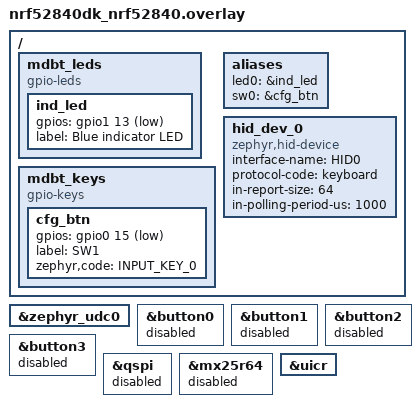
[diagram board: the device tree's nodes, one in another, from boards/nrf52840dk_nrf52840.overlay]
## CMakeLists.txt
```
# SPDX-License-Identifier: Apache-2.0

cmake_minimum_required(VERSION 3.20.0)
find_package(Zephyr REQUIRED HINTS $ENV{ZEPHYR_BASE})
project(ble_password)

include(${ZEPHYR_BASE}/samples/subsys/usb/common/common.cmake)
FILE(GLOB app_sources src/*.c)
target_sources(app PRIVATE ${app_sources})

# The app is an MCUboot image (sysbuild.conf); BLE update packages come from
# sysbuild as <build>/dfu_application.zip.  The official dongle's one-time
# Nordic-bootloader migration package (MCUboot only) is made in sysbuild.cmake.
```

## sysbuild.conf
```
# Both boards run the app under MCUboot so it can be updated over BLE (SMP)
# from the companion Android app.  Flash layouts: pm_static_<board>.yml.
# MCUboot's own config: sysbuild/mcuboot/.
SB_CONFIG_BOOTLOADER_MCUBOOT=y
```

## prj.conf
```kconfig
# BLE Observer (beacon scanning) + Peripheral (GATT config service)
CONFIG_BT=y
CONFIG_BT_OBSERVER=y
CONFIG_BT_PERIPHERAL=y
CONFIG_BT_DEVICE_NAME="BLE_Password"
CONFIG_BT_LOG_LEVEL_WRN=y

# Large ATT MTU / data length: a full password fits in one GATT write, and
# SMP firmware upload runs at a usable speed.
CONFIG_BT_L2CAP_TX_MTU=498
CONFIG_BT_BUF_ACL_TX_SIZE=502
CONFIG_BT_BUF_ACL_RX_SIZE=502
CONFIG_BT_CTLR_DATA_LENGTH_MAX=251

# Persist config in flash via the RAW flash API at the 'config_storage'
# partition (pm_static_*.yml).  Flash uses the default MPSL radio sync so SMP
# can erase/write the upload slot DURING a BLE connection; the config save
# still runs with bt_disable() as before.
CONFIG_FLASH=y
CONFIG_FLASH_MAP=y

# --- Firmware update: MCUboot + MCUmgr/SMP over BLE -----------------------
# MCUboot itself is enabled in sysbuild.conf.  SMP is locked by the app (see
# smp_gate_cb in main.c) unless DFU was armed with the button held.
CONFIG_ZCBOR=y
CONFIG_NET_BUF=y
CONFIG_CRC=y
CONFIG_MCUMGR=y
CONFIG_MCUMGR_TRANSPORT_BT=y
CONFIG_MCUMGR_TRANSPORT_BT_REASSEMBLY=y
CONFIG_MCUMGR_TRANSPORT_BT_CONN_PARAM_CONTROL=y
CONFIG_MCUMGR_TRANSPORT_NETBUF_SIZE=2475
CONFIG_MCUMGR_TRANSPORT_WORKQUEUE_STACK_SIZE=4608
CONFIG_MCUMGR_GRP_IMG=y
CONFIG_MCUMGR_GRP_OS=y
CONFIG_MCUMGR_GRP_OS_MCUMGR_PARAMS=y
CONFIG_MCUMGR_MGMT_NOTIFICATION_HOOKS=y
CONFIG_MCUMGR_SMP_COMMAND_STATUS_HOOKS=y
CONFIG_IMG_MANAGER=y
CONFIG_STREAM_FLASH=y
# SMP "reset" after an upload.
CONFIG_REBOOT=y

# --- Encrypted config session (fw 1.2.0+) ----------------------------------
# P-256 ECDH via PSA crypto on the CC310 (src/cfg_crypto.h); the KDF/sealing is
# our own HMAC code.  ECDH runs in the BT RX thread (GATT write), so its stack
# is enlarged.
CONFIG_NRF_SECURITY=y
CONFIG_MBEDTLS_PSA_CRYPTO_C=y
CONFIG_PSA_WANT_ALG_ECDH=y
CONFIG_PSA_WANT_ECC_SECP_R1_256=y
CONFIG_PSA_WANT_KEY_TYPE_ECC_KEY_PAIR_GENERATE=y
CONFIG_PSA_WANT_KEY_TYPE_ECC_KEY_PAIR_IMPORT=y
CONFIG_PSA_WANT_KEY_TYPE_ECC_KEY_PAIR_EXPORT=y
CONFIG_PSA_WANT_KEY_TYPE_ECC_KEY_PAIR_DERIVE=y
CONFIG_PSA_WANT_KEY_TYPE_ECC_PUBLIC_KEY=y
CONFIG_PSA_WANT_GENERATE_RANDOM=y
CONFIG_BT_RX_STACK_SIZE=4096

# Hardware watchdog (fail closed: a hang/crash resets the dongle and that boot
# locks the PC) + reset-cause readout.  MCUboot feeds it during swaps.
CONFIG_WATCHDOG=y
CONFIG_HWINFO=y

# USB HID — new stack (avoids dual-stack linker conflict seen on nRF52840 Dongle)
CONFIG_USB_DEVICE_STACK_NEXT=y
CONFIG_USB_DEVICE_STACK=n
CONFIG_USBD_HID_SUPPORT=y
CONFIG_USBD_LOG_LEVEL_WRN=y
CONFIG_USBD_HID_LOG_LEVEL_WRN=y
CONFIG_UDC_DRIVER_LOG_LEVEL_WRN=y
CONFIG_SAMPLE_USBD_PID=0x0008

# GPIO + button input subsystem
CONFIG_GPIO=y
CONFIG_INPUT=y
CONFIG_INPUT_MODE_SYNCHRONOUS=y

# Logging — disabled; CDC ACM serial removed so USB is HID-only
# (CDC ACM composite with HID is unstable on this dongle / next USB stack).
CONFIG_LOG=n
CONFIG_UART_CONSOLE=n
CONFIG_BOARD_SERIAL_BACKEND_CDC_ACM=n

# Larger stacks for BLE + USB combo
CONFIG_MAIN_STACK_SIZE=4096
CONFIG_SYSTEM_WORKQUEUE_STACK_SIZE=4096
```

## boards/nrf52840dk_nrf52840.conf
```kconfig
# Board-specific config for the 3rd-party Raytac MDBT50Q-RX dongle
# (built on the nrf52840dk target, flashed via J-Link).

# The module's 32.768 kHz crystal is optional / may not be populated, and the
# DK target defaults to the external crystal (LFXO).  Use the internal RC
# oscillator so BLE's low-frequency clock starts without a crystal — otherwise
# bt_enable() stalls and the app never reaches the config window.
CONFIG_CLOCK_CONTROL_NRF_K32SRC_RC=y

# Debug logging over SEGGER RTT (read with J-Link; this board has SWD).
CONFIG_LOG=y
CONFIG_LOG_MODE_DEFERRED=y
CONFIG_USE_SEGGER_RTT=y
CONFIG_LOG_BACKEND_RTT=y
CONFIG_LOG_BACKEND_UART=n
CONFIG_CONSOLE=n
CONFIG_UART_CONSOLE=n

# MCUboot + MCUmgr/SMP (firmware update over BLE) are common to both boards:
# see prj.conf, sysbuild.conf and sysbuild/mcuboot/.
```

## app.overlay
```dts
/*
 * LEDs and button use the nRF52840 Dongle board aliases directly:
 *   led0  = green single LED  (P0.06)
 *   led1  = RGB red           (P0.08)
 *   led3  = RGB blue          (P0.12)
 *   sw0   = SW1 button        (P1.06) — already wired to INPUT_KEY_0 by board DTS
 */

/ {
	hid_dev_0: hid_dev_0 {
		compatible = "zephyr,hid-device";
		interface-name = "HID0";
		protocol-code = "keyboard";
		in-report-size = <64>;
		in-polling-period-us = <1000>;
	};
};
```

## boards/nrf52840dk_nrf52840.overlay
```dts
/*
 * Overlay for the 3rd-party Raytac MDBT50Q-RX USB dongle, built on the
 * nrf52840dk board target (which boots from 0x0 → flashed standalone via J-Link).
 *
 * Board hardware:
 *   - single blue LED on P1.13 (active low)   (D2/P1.11 is not populated)
 *   - button on P0.15 (active low, pull-up)
 *   - USB on the nRF52840 USB peripheral
 */
#include <zephyr/dt-bindings/gpio/gpio.h>
#include <zephyr/dt-bindings/input/input-event-codes.h>

/ {
	mdbt_leds {
		compatible = "gpio-leds";
		ind_led: ind_led {
			gpios = <&gpio1 13 GPIO_ACTIVE_LOW>;
			label = "Blue indicator LED";
		};
	};

	mdbt_keys {
		compatible = "gpio-keys";
		cfg_btn: cfg_btn {
			gpios = <&gpio0 15 (GPIO_ACTIVE_LOW | GPIO_PULL_UP)>;
			label = "SW1";
			zephyr,code = <INPUT_KEY_0>;
		};
	};

	aliases {
		led0 = &ind_led;
		sw0 = &cfg_btn;
	};

	/* USB HID keyboard (same as the app.overlay used for the dongle build). */
	hid_dev_0: hid_dev_0 {
		compatible = "zephyr,hid-device";
		interface-name = "HID0";
		protocol-code = "keyboard";
		in-report-size = <64>;
		in-polling-period-us = <1000>;
	};
};

/* Make sure the USB device controller is available for HID. */
&zephyr_udc0 {
	status = "okay";
};

/* Disable the DK's on-board buttons so their pins (P0.11 etc.) don't emit
 * INPUT_KEY_0 and interfere with our button on P0.15. */
&button0 { status = "disabled"; };
&button1 { status = "disabled"; };
&button2 { status = "disabled"; };
&button3 { status = "disabled"; };

/* On the MDBT50Q-RX, module pins P0.18 (nRESET) and P0.19 are tied together.
 * The DK's QSPI flash (not fitted here) has SCK on P0.19: the QSPI driver
 * pulled the reset pin low and reset-looped the chip before main(), so SWD
 * couldn't even power up the DAP ("bricked" two units). Drop the QSPI flash,
 * and don't make P0.18 a reset pin (the DK writes UICR.PSELRESET at boot). */
&qspi { status = "disabled"; };
&mx25r64 { status = "disabled"; };
&uicr { /delete-property/ gpio-as-nreset; };
```

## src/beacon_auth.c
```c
/*
 * SPDX-License-Identifier: Apache-2.0
 *
 * SHA-256 / HMAC-SHA256 and the rolling-beacon check (see beacon_auth.h).
 * SHA-256 follows FIPS 180-4; verified against the FIPS and RFC 4231 vectors
 * in tests/host/beacon_auth_test.c.
 */
#include "beacon_auth.h"

#include <string.h>

struct sha256_ctx {
	uint32_t h[8];
	uint8_t  block[64];
	size_t   used;     /* bytes in block */
	uint64_t total;    /* message length in bytes */
};

static const uint32_t K[64] = {
	0x428a2f98, 0x71374491, 0xb5c0fbcf, 0xe9b5dba5, 0x3956c25b, 0x59f111f1,
	0x923f82a4, 0xab1c5ed5, 0xd807aa98, 0x12835b01, 0x243185be, 0x550c7dc3,
	0x72be5d74, 0x80deb1fe, 0x9bdc06a7, 0xc19bf174, 0xe49b69c1, 0xefbe4786,
	0x0fc19dc6, 0x240ca1cc, 0x2de92c6f, 0x4a7484aa, 0x5cb0a9dc, 0x76f988da,
	0x983e5152, 0xa831c66d, 0xb00327c8, 0xbf597fc7, 0xc6e00bf3, 0xd5a79147,
	0x06ca6351, 0x14292967, 0x27b70a85, 0x2e1b2138, 0x4d2c6dfc, 0x53380d13,
	0x650a7354, 0x766a0abb, 0x81c2c92e, 0x92722c85, 0xa2bfe8a1, 0xa81a664b,
	0xc24b8b70, 0xc76c51a3, 0xd192e819, 0xd6990624, 0xf40e3585, 0x106aa070,
	0x19a4c116, 0x1e376c08, 0x2748774c, 0x34b0bcb5, 0x391c0cb3, 0x4ed8aa4a,
	0x5b9cca4f, 0x682e6ff3, 0x748f82ee, 0x78a5636f, 0x84c87814, 0x8cc70208,
	0x90befffa, 0xa4506ceb, 0xbef9a3f7, 0xc67178f2,
};

static uint32_t rotr(uint32_t x, unsigned int n)
{
	return (x >> n) | (x << (32u - n));
}

static void sha256_compress(struct sha256_ctx *c, const uint8_t *p)
{
	uint32_t w[64];

	for (int i = 0; i < 16; i++) {
		w[i] = ((uint32_t)p[4 * i] << 24) | ((uint32_t)p[4 * i + 1] << 16) |
		       ((uint32_t)p[4 * i + 2] << 8) | (uint32_t)p[4 * i + 3];
	}
	for (int i = 16; i < 64; i++) {
		uint32_t s0 = rotr(w[i - 15], 7) ^ rotr(w[i - 15], 18) ^ (w[i - 15] >> 3);
		uint32_t s1 = rotr(w[i - 2], 17) ^ rotr(w[i - 2], 19) ^ (w[i - 2] >> 10);

		w[i] = w[i - 16] + s0 + w[i - 7] + s1;
	}

	uint32_t a = c->h[0], b = c->h[1], cc = c->h[2], d = c->h[3];
	uint32_t e = c->h[4], f = c->h[5], g = c->h[6], h = c->h[7];

	for (int i = 0; i < 64; i++) {
		uint32_t s1 = rotr(e, 6) ^ rotr(e, 11) ^ rotr(e, 25);
		uint32_t ch = (e & f) ^ (~e & g);
		uint32_t t1 = h + s1 + ch + K[i] + w[i];
		uint32_t s0 = rotr(a, 2) ^ rotr(a, 13) ^ rotr(a, 22);
		uint32_t maj = (a & b) ^ (a & cc) ^ (b & cc);
		uint32_t t2 = s0 + maj;

		h = g;
		g = f;
		f = e;
		e = d + t1;
		d = cc;
		cc = b;
		b = a;
		a = t1 + t2;
	}

	c->h[0] += a;
	c->h[1] += b;
	c->h[2] += cc;
	c->h[3] += d;
	c->h[4] += e;
	c->h[5] += f;
	c->h[6] += g;
	c->h[7] += h;
}

static void sha256_init(struct sha256_ctx *c)
{
	static const uint32_t iv[8] = {
		0x6a09e667, 0xbb67ae85, 0x3c6ef372, 0xa54ff53a,
		0x510e527f, 0x9b05688c, 0x1f83d9ab, 0x5be0cd19,
	};

	memcpy(c->h, iv, sizeof(iv));
	c->used = 0;
	c->total = 0;
}

static void sha256_update(struct sha256_ctx *c, const uint8_t *p, size_t len)
{
	c->total += len;
	while (len > 0) {
		size_t n = sizeof(c->block) - c->used;

		if (n > len) {
			n = len;
		}
		memcpy(c->block + c->used, p, n);
		c->used += n;
		p += n;
		len -= n;
		if (c->used == sizeof(c->block)) {
			sha256_compress(c, c->block);
			c->used = 0;
		}
	}
}

static void sha256_final(struct sha256_ctx *c, uint8_t out[SHA256_DIGEST_LEN])
{
	uint64_t bits = c->total * 8u;
	uint8_t pad = 0x80;

	sha256_update(c, &pad, 1);
	pad = 0;
	while (c->used != 56) {
		sha256_update(c, &pad, 1);
	}
	uint8_t len_be[8];

	for (int i = 0; i < 8; i++) {
		len_be[i] = (uint8_t)(bits >> (56 - 8 * i));
	}
	sha256_update(c, len_be, sizeof(len_be));

	for (int i = 0; i < 8; i++) {
		out[4 * i]     = (uint8_t)(c->h[i] >> 24);
		out[4 * i + 1] = (uint8_t)(c->h[i] >> 16);
		out[4 * i + 2] = (uint8_t)(c->h[i] >> 8);
		out[4 * i + 3] = (uint8_t)c->h[i];
	}
}

void sha256(const uint8_t *msg, size_t len, uint8_t out[SHA256_DIGEST_LEN])
{
	struct sha256_ctx c;

	sha256_init(&c);
	sha256_update(&c, msg, len);
	sha256_final(&c, out);
}

void hmac_sha256(const uint8_t *key, size_t key_len,
		 const uint8_t *msg, size_t msg_len,
		 uint8_t out[SHA256_DIGEST_LEN])
{
	uint8_t pad[64];
	uint8_t inner[SHA256_DIGEST_LEN];
	struct sha256_ctx c;

	if (key_len > sizeof(pad)) {
		key_len = sizeof(pad);   /* not used with long keys; see header */
	}

	memset(pad, 0x36, sizeof(pad));
	for (size_t i = 0; i < key_len; i++) {
		pad[i] ^= key[i];
	}
	sha256_init(&c);
	sha256_update(&c, pad, sizeof(pad));
	sha256_update(&c, msg, msg_len);
	sha256_final(&c, inner);

	memset(pad, 0x5c, sizeof(pad));
	for (size_t i = 0; i < key_len; i++) {
		pad[i] ^= key[i];
	}
	sha256_init(&c);
	sha256_update(&c, pad, sizeof(pad));
	sha256_update(&c, inner, sizeof(inner));
	sha256_final(&c, out);

	memset(pad, 0, sizeof(pad));
}

bool beacon_auth_is_beacon(const uint8_t *mfg, size_t len)
{
	return len == BEACON_MFG_LEN &&
	       mfg[0] == (uint8_t)(BEACON_COMPANY_ID & 0xFF) &&
	       mfg[1] == (uint8_t)(BEACON_COMPANY_ID >> 8) &&
	       mfg[2] == BEACON_MAGIC0 && mfg[3] == BEACON_MAGIC1 &&
	       mfg[4] == BEACON_VERSION;
}

bool beacon_auth_verify(const uint8_t key[BEACON_KEY_LEN],
			const uint8_t *mfg, size_t len, uint32_t *ctr)
{
	if (!beacon_auth_is_beacon(mfg, len)) {
		return false;
	}

	/* Signed part: magic, version, counter (7 bytes after the company ID). */
	uint8_t mac[SHA256_DIGEST_LEN];

	hmac_sha256(key, BEACON_KEY_LEN, &mfg[2], 7, mac);

	/* Constant-time compare. */
	uint8_t diff = 0;

	for (int i = 0; i < BEACON_TAG_LEN; i++) {
		diff |= (uint8_t)(mac[i] ^ mfg[9 + i]);
	}
	if (diff != 0) {
		return false;
	}

	*ctr = (uint32_t)mfg[5] | ((uint32_t)mfg[6] << 8) |
	       ((uint32_t)mfg[7] << 16) | ((uint32_t)mfg[8] << 24);
	return true;
}

void beacon_auth_key_id(const uint8_t key[BEACON_KEY_LEN],
			uint8_t id[BEACON_KEY_ID_LEN])
{
	static const uint8_t label[] = "BLEPW-KEYID";
	uint8_t mac[SHA256_DIGEST_LEN];

	hmac_sha256(key, BEACON_KEY_LEN, label, sizeof(label) - 1, mac);
	memcpy(id, mac, BEACON_KEY_ID_LEN);
}
```

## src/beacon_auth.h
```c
/*
 * SPDX-License-Identifier: Apache-2.0
 *
 * Authenticated rolling beacon (fw 1.2.0+).
 *
 * The phone advertises manufacturer-specific data (company ID 0xFFFF, the
 * SIG's "internal use / testing" ID) laid out as:
 *
 *   FF FF  'B' 'P'  01  ctr[4, LE]  tag[8]          (17 bytes)
 *
 *   ctr = phone wall clock in seconds, strictly increasing (never repeats a
 *         lower value, even if the phone's clock is set back)
 *   tag = first 8 bytes of HMAC-SHA256(key, 'B' 'P' 01 ctr[4])
 *
 * key is a random 128-bit secret made by the phone and written to the dongle
 * once (button held, config window).  Each phone has its own key, so dongles
 * ignore every other phone's beacon; a recorded beacon is rejected because its
 * counter is stale.  This module is plain C with no Zephyr dependencies so it
 * can be unit-tested on the host (tests/host/).
 */
#ifndef BEACON_AUTH_H_
#define BEACON_AUTH_H_

#include <stdbool.h>
#include <stddef.h>
#include <stdint.h>

#define BEACON_COMPANY_ID   0xFFFFu
#define BEACON_MAGIC0       0x42u   /* 'B' */
#define BEACON_MAGIC1       0x50u   /* 'P' */
#define BEACON_VERSION      0x01u
#define BEACON_KEY_LEN      16
#define BEACON_TAG_LEN      8
#define BEACON_KEY_ID_LEN   4
/* Manufacturer data as the scanner sees it, company ID included. */
#define BEACON_MFG_LEN      (2 + 2 + 1 + 4 + BEACON_TAG_LEN)

#define SHA256_DIGEST_LEN   32

void sha256(const uint8_t *msg, size_t len, uint8_t out[SHA256_DIGEST_LEN]);

/* HMAC-SHA256 (RFC 2104).  key_len must be <= 64 (we only use 16-byte keys). */
void hmac_sha256(const uint8_t *key, size_t key_len,
		 const uint8_t *msg, size_t msg_len,
		 uint8_t out[SHA256_DIGEST_LEN]);

/* Check one manufacturer-data field (company ID first).  Returns true and sets
 * *ctr if it is our beacon format AND the tag verifies with key.  Freshness
 * (the counter check) is the caller's job. */
bool beacon_auth_verify(const uint8_t key[BEACON_KEY_LEN],
			const uint8_t *mfg, size_t len, uint32_t *ctr);

/* True if mfg is our beacon format (regardless of whose key made it). */
bool beacon_auth_is_beacon(const uint8_t *mfg, size_t len);

/* Short, non-secret identifier of a key: HMAC(key, "BLEPW-KEYID")[0..4].
 * Lets the app tell whether a dongle already holds its key without the key
 * ever being sent again. */
void beacon_auth_key_id(const uint8_t key[BEACON_KEY_LEN],
			uint8_t id[BEACON_KEY_ID_LEN]);

#endif /* BEACON_AUTH_H_ */
```

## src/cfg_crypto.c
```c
/*
 * SPDX-License-Identifier: Apache-2.0
 *
 * Encrypted config session: HKDF + HMAC-based encrypt-then-MAC (see cfg_crypto.h).
 */
#include "cfg_crypto.h"
#include "beacon_auth.h"

#include <string.h>

/* Largest sealed plaintext we handle (a 64-char password + NUL headroom). */
#define CFG_MAX_PT 80

/* Append the HKDF info (id_pub || dongle_pub || phone_pub) at buf+off. */
static size_t cfg_info(uint8_t *buf, size_t off, const uint8_t id_pub[CFG_PUB_LEN],
		       const uint8_t dongle_pub[CFG_PUB_LEN],
		       const uint8_t phone_pub[CFG_PUB_LEN])
{
	memcpy(buf + off, id_pub, CFG_PUB_LEN);
	off += CFG_PUB_LEN;
	memcpy(buf + off, dongle_pub, CFG_PUB_LEN);
	off += CFG_PUB_LEN;
	memcpy(buf + off, phone_pub, CFG_PUB_LEN);
	off += CFG_PUB_LEN;
	return off;
}

void cfg_session_derive(const uint8_t z1[CFG_SECRET_LEN],
			const uint8_t z2[CFG_SECRET_LEN],
			const uint8_t id_pub[CFG_PUB_LEN],
			const uint8_t dongle_pub[CFG_PUB_LEN],
			const uint8_t phone_pub[CFG_PUB_LEN],
			uint8_t k_enc[CFG_SUBKEY_LEN],
			uint8_t k_mac[CFG_SUBKEY_LEN])
{
	static const uint8_t salt[] = "BLEPW-SESSION-v2";
	uint8_t ikm[2 * CFG_SECRET_LEN];
	uint8_t prk[SHA256_DIGEST_LEN];
	/* T(2) input is the longest: T(1) || info || 0x02 (info = 3 public keys) */
	uint8_t buf[SHA256_DIGEST_LEN + 3 * CFG_PUB_LEN + 1];
	size_t n;

	/* HKDF-Extract over both shared secrets. */
	memcpy(ikm, z1, CFG_SECRET_LEN);
	memcpy(ikm + CFG_SECRET_LEN, z2, CFG_SECRET_LEN);
	hmac_sha256(salt, sizeof(salt) - 1, ikm, sizeof(ikm), prk);

	/* HKDF-Expand: T(1) = HMAC(PRK, info || 01) */
	n = cfg_info(buf, 0, id_pub, dongle_pub, phone_pub);
	buf[n++] = 0x01;
	hmac_sha256(prk, sizeof(prk), buf, n, k_enc);

	/* T(2) = HMAC(PRK, T(1) || info || 02) */
	memcpy(buf, k_enc, SHA256_DIGEST_LEN);
	n = cfg_info(buf, SHA256_DIGEST_LEN, id_pub, dongle_pub, phone_pub);
	buf[n++] = 0x02;
	hmac_sha256(prk, sizeof(prk), buf, n, k_mac);

	memset(ikm, 0, sizeof(ikm));
	memset(prk, 0, sizeof(prk));
	memset(buf, 0, sizeof(buf));
}

static void put_le32(uint8_t *p, uint32_t v)
{
	p[0] = (uint8_t)v;
	p[1] = (uint8_t)(v >> 8);
	p[2] = (uint8_t)(v >> 16);
	p[3] = (uint8_t)(v >> 24);
}

/* XOR data with the keystream for (id, seq). */
static void cfg_xor_stream(const uint8_t k_enc[CFG_SUBKEY_LEN], uint8_t id,
			   const uint8_t seq_le[4], uint8_t *data, size_t len)
{
	uint8_t msg[6];
	uint8_t block[SHA256_DIGEST_LEN];

	msg[0] = id;
	memcpy(&msg[1], seq_le, 4);
	for (size_t off = 0, j = 0; off < len; off += sizeof(block), j++) {
		msg[5] = (uint8_t)j;
		hmac_sha256(k_enc, CFG_SUBKEY_LEN, msg, sizeof(msg), block);
		for (size_t i = 0; i < sizeof(block) && off + i < len; i++) {
			data[off + i] ^= block[i];
		}
	}
	memset(block, 0, sizeof(block));
}

static void cfg_tag(const uint8_t k_mac[CFG_SUBKEY_LEN], uint8_t id,
		    const uint8_t seq_le[4], const uint8_t *ct, size_t ct_len,
		    uint8_t tag[SHA256_DIGEST_LEN])
{
	uint8_t msg[1 + 4 + CFG_MAX_PT];

	msg[0] = id;
	memcpy(&msg[1], seq_le, 4);
	memcpy(&msg[5], ct, ct_len);
	hmac_sha256(k_mac, CFG_SUBKEY_LEN, msg, 5 + ct_len, tag);
}

int cfg_open(const uint8_t k_enc[CFG_SUBKEY_LEN], const uint8_t k_mac[CFG_SUBKEY_LEN],
	     uint8_t id, uint32_t *last_seq,
	     const uint8_t *in, size_t in_len, uint8_t *out, size_t out_max)
{
	if (in_len < CFG_SEAL_OVERHEAD) {
		return -1;
	}
	size_t ct_len = in_len - CFG_SEAL_OVERHEAD;

	if (ct_len > out_max || ct_len > CFG_MAX_PT) {
		return -1;
	}

	const uint8_t *seq_le = in;
	const uint8_t *ct = in + 4;
	const uint8_t *tag_in = in + 4 + ct_len;
	uint8_t tag[SHA256_DIGEST_LEN];
	uint8_t diff = 0;

	cfg_tag(k_mac, id, seq_le, ct, ct_len, tag);
	for (int i = 0; i < CFG_SEAL_TAG_LEN; i++) {
		diff |= (uint8_t)(tag[i] ^ tag_in[i]);
	}
	if (diff != 0) {
		return -1;
	}

	uint32_t seq = (uint32_t)seq_le[0] | ((uint32_t)seq_le[1] << 8) |
		       ((uint32_t)seq_le[2] << 16) | ((uint32_t)seq_le[3] << 24);

	if (seq <= *last_seq) {
		return -1;   /* replayed within this session */
	}
	*last_seq = seq;

	memcpy(out, ct, ct_len);
	cfg_xor_stream(k_enc, id, seq_le, out, ct_len);
	return (int)ct_len;
}

size_t cfg_seal(const uint8_t k_enc[CFG_SUBKEY_LEN], const uint8_t k_mac[CFG_SUBKEY_LEN],
		uint8_t id, uint32_t seq,
		const uint8_t *pt, size_t pt_len, uint8_t *out)
{
	uint8_t tag[SHA256_DIGEST_LEN];

	put_le32(out, seq);
	memcpy(out + 4, pt, pt_len);
	cfg_xor_stream(k_enc, id, out, out + 4, pt_len);
	cfg_tag(k_mac, id, out, out + 4, pt_len, tag);
	memcpy(out + 4 + pt_len, tag, CFG_SEAL_TAG_LEN);
	return pt_len + CFG_SEAL_OVERHEAD;
}
```

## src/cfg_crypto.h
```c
/*
 * SPDX-License-Identifier: Apache-2.0
 *
 * Encrypted config session (fw 1.2.0+): the secrets the app writes (passwords,
 * username 2, the beacon key) travel encrypted, not in the clear.
 *
 * AUTHENTICATED since fw 1.4.0 (static-ephemeral ECDH, Noise "NK" style): the
 * dongle has a persistent P-256 IDENTITY key pair, and the session key is
 * derived from TWO shared secrets, so only the real dongle (holding the identity
 * private key) can derive it, and the app pins the identity public key.
 *
 *   1. Per connection, the phone reads the dongle's EPHEMERAL public key (fresh
 *      per window) and its IDENTITY public key (persistent), and writes its own
 *      fresh ephemeral key (all 65-byte uncompressed points).
 *        z1 = ECDH(ephemeral_dongle, ephemeral_phone)   (forward secrecy)
 *        z2 = ECDH(identity_dongle,  ephemeral_phone)    (authenticates the dongle)
 *   2. HKDF-SHA256 (RFC 5869), salt "BLEPW-SESSION-v2", IKM = z1 || z2,
 *      info = id_pub || dongle_pub || phone_pub, L = 64 → k_enc (32) || k_mac (32).
 *   3. Each secret write is  seq[4, LE] || ct || tag[16]  where
 *        ct  = pt XOR (HMAC(k_enc, id || seq || 0) || HMAC(k_enc, id || seq || 1) || …)
 *        tag = HMAC(k_mac, id || seq || ct)[0..16]
 *      id = the characteristic's short ID (low byte of its UUID, e.g. 0x02),
 *      so a ciphertext can't be moved to another characteristic; seq must go
 *      up within a session, so it can't be replayed.
 *
 * This stops passive sniffing AND (with the app pinning the identity key) an
 * active relay/fake dongle: a relay can't compute z2 (it lacks the identity
 * private key), so it can't derive the session key.
 *
 * Plain C, no Zephyr dependencies (the ECDH itself is PSA, in main.c), so it is
 * unit-tested on the host (tests/host/).
 */
#ifndef CFG_CRYPTO_H_
#define CFG_CRYPTO_H_

#include <stddef.h>
#include <stdint.h>

#define CFG_PUB_LEN        65   /* 0x04 || X || Y */
#define CFG_SECRET_LEN     32   /* ECDH x-coordinate */
#define CFG_SUBKEY_LEN     32
#define CFG_SEAL_TAG_LEN   16
#define CFG_SEAL_OVERHEAD  (4 + CFG_SEAL_TAG_LEN)

/* Derive the session keys from the ephemeral (z1) and identity (z2) ECDH shared
 * secrets.  id_pub is the dongle's persistent identity public key. */
void cfg_session_derive(const uint8_t z1[CFG_SECRET_LEN],
			const uint8_t z2[CFG_SECRET_LEN],
			const uint8_t id_pub[CFG_PUB_LEN],
			const uint8_t dongle_pub[CFG_PUB_LEN],
			const uint8_t phone_pub[CFG_PUB_LEN],
			uint8_t k_enc[CFG_SUBKEY_LEN],
			uint8_t k_mac[CFG_SUBKEY_LEN]);

/* Verify and decrypt one sealed write.  *last_seq is the highest seq accepted
 * this session (start at 0) and is updated on success.  Returns the plaintext
 * length, or -1 if the tag is wrong, seq isn't newer, or out is too small. */
int cfg_open(const uint8_t k_enc[CFG_SUBKEY_LEN], const uint8_t k_mac[CFG_SUBKEY_LEN],
	     uint8_t id, uint32_t *last_seq,
	     const uint8_t *in, size_t in_len, uint8_t *out, size_t out_max);

/* The phone's side (used by the host test to round-trip).  out must hold
 * pt_len + CFG_SEAL_OVERHEAD bytes; returns that length. */
size_t cfg_seal(const uint8_t k_enc[CFG_SUBKEY_LEN], const uint8_t k_mac[CFG_SUBKEY_LEN],
		uint8_t id, uint32_t seq,
		const uint8_t *pt, size_t pt_len, uint8_t *out);

#endif /* CFG_CRYPTO_H_ */
```
